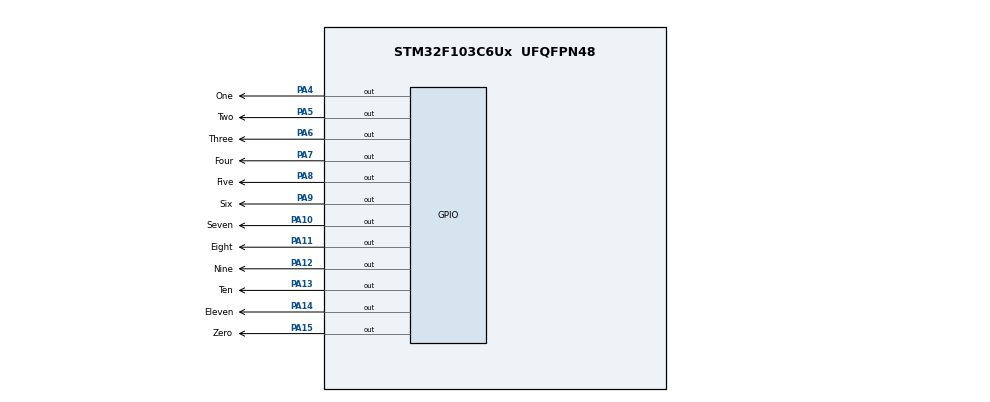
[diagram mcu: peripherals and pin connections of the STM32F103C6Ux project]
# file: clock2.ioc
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Mcu.Family=STM32F1
Mcu.Name=STM32F103C6Ux
Mcu.Package=UFQFPN48
NVIC.PriorityGroup=NVIC_PRIORITYGROUP_4
PA10.GPIO_Label=Seven
PA10.Signal=GPIO_Output
PA11.GPIO_Label=Eight
PA11.Signal=GPIO_Output
PA12.GPIO_Label=Nine
PA12.Signal=GPIO_Output
PA13.GPIO_Label=Ten
PA13.Signal=GPIO_Output
PA14.GPIO_Label=Eleven
PA14.Signal=GPIO_Output
PA15.GPIO_Label=Zero
PA15.Signal=GPIO_Output
PA4.GPIO_Label=One
PA4.Signal=GPIO_Output
PA5.GPIO_Label=Two
PA5.Signal=GPIO_Output
PA6.GPIO_Label=Three
PA6.Signal=GPIO_Output
PA7.GPIO_Label=Four
PA7.Signal=GPIO_Output
PA8.GPIO_Label=Five
PA8.Signal=GPIO_Output
PA9.GPIO_Label=Six
PA9.Signal=GPIO_Output
ProjectManager.HeapSize=0x200
ProjectManager.StackSize=0x400
ProjectManager.TargetToolchain=STM32CubeIDE
RCC.APB1Freq_Value=8000000
RCC.APB2Freq_Value=8000000
VP_SYS_VS_ND.Mode=No_Debug
board=custom

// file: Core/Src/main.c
/* USER CODE BEGIN Header */
/**
  ******************************************************************************
  * @file           : main.c
  * @brief          : Main program body
  ******************************************************************************
  * @attention
  *
  * <h2><center>&copy; Copyright (c) 2025 STMicroelectronics.
  * All rights reserved.</center></h2>
  *
  * This software component is licensed by ST under BSD 3-Clause license,
  * the "License"; You may not use this file except in compliance with the
  * License. You may obtain a copy of the License at:
  *                        opensource.org/licenses/BSD-3-Clause
  *
  ******************************************************************************
  */
/* USER CODE END Header */
#include "main.h"

void SystemClock_Config(void);
static void MX_GPIO_Init(void);

void setNumberOnClock(int num) {
	switch (num) {
		  case 0: HAL_GPIO_WritePin(Zero_GPIO_Port, Zero_Pin, SET); break;
		  case 1: HAL_GPIO_WritePin(One_GPIO_Port, One_Pin, SET); break;
		  case 2: HAL_GPIO_WritePin(Two_GPIO_Port, Two_Pin, SET); break;
		  case 3: HAL_GPIO_WritePin(Three_GPIO_Port, Three_Pin, SET); break;
		  case 4: HAL_GPIO_WritePin(Four_GPIO_Port, Four_Pin, SET); break;
		  case 5: HAL_GPIO_WritePin(Five_GPIO_Port, Five_Pin, SET); break;
		  case 6: HAL_GPIO_WritePin(Six_GPIO_Port, Six_Pin, SET); break;
		  case 7: HAL_GPIO_WritePin(Seven_GPIO_Port, Seven_Pin, SET); break;
		  case 8: HAL_GPIO_WritePin(Eight_GPIO_Port, Eight_Pin, SET); break;
		  case 9: HAL_GPIO_WritePin(Nine_GPIO_Port, Nine_Pin, SET); break;
		  case 10: HAL_GPIO_WritePin(Ten_GPIO_Port, Ten_Pin, SET); break;
		  case 11: HAL_GPIO_WritePin(Eleven_GPIO_Port, Eleven_Pin, SET); break;
		  default: break;
	}
}
void clearNumberOnClock(int num){
	switch (num) {
		  case 0: HAL_GPIO_WritePin(Zero_GPIO_Port, Zero_Pin, RESET); break;
		  case 1: HAL_GPIO_WritePin(One_GPIO_Port, One_Pin, RESET); break;
		  case 2: HAL_GPIO_WritePin(Two_GPIO_Port, Two_Pin, RESET); break;
		  case 3: HAL_GPIO_WritePin(Three_GPIO_Port, Three_Pin, RESET); break;
		  case 4: HAL_GPIO_WritePin(Four_GPIO_Port, Four_Pin, RESET); break;
		  case 5: HAL_GPIO_WritePin(Five_GPIO_Port, Five_Pin, RESET); break;
		  case 6: HAL_GPIO_WritePin(Six_GPIO_Port, Six_Pin, RESET); break;
		  case 7: HAL_GPIO_WritePin(Seven_GPIO_Port, Seven_Pin, RESET); break;
		  case 8: HAL_GPIO_WritePin(Eight_GPIO_Port, Eight_Pin, RESET); break;
		  case 9: HAL_GPIO_WritePin(Nine_GPIO_Port, Nine_Pin, RESET); break;
		  case 10: HAL_GPIO_WritePin(Ten_GPIO_Port, Ten_Pin, RESET); break;
		  case 11: HAL_GPIO_WritePin(Eleven_GPIO_Port, Eleven_Pin, RESET); break;
		  default: break;
	}
}

int main(void)
{

  /* MCU Configuration--------------------------------------------------------*/

  /* Reset of all peripherals, Initializes the Flash interface and the Systick. */
  HAL_Init();

  /* Configure the system clock */
  SystemClock_Config();

  /* Initialize all configured peripherals */
  MX_GPIO_Init();

  /* Infinite loop */
  /* USER CODE BEGIN WHILE */

  int step = 0;

  while (1)
  {
	  setNumberOnClock(step);
	  HAL_Delay(1000);
	  clearNumberOnClock(step);
	  step++;
	  if (step >= 12) step = 0;

    /* USER CODE END WHILE */

  }
}

void SystemClock_Config(void)
{
  RCC_OscInitTypeDef RCC_OscInitStruct = {0};
  RCC_ClkInitTypeDef RCC_ClkInitStruct = {0};

  /** Initializes the RCC Oscillators according to the specified parameters
  * in the RCC_OscInitTypeDef structure.
  */
  RCC_OscInitStruct.OscillatorType = RCC_OSCILLATORTYPE_HSI;
  RCC_OscInitStruct.HSIState = RCC_HSI_ON;
  RCC_OscInitStruct.HSICalibrationValue = RCC_HSICALIBRATION_DEFAULT;
  RCC_OscInitStruct.PLL.PLLState = RCC_PLL_NONE;
  if (HAL_RCC_OscConfig(&RCC_OscInitStruct) != HAL_OK)
  {
    Error_Handler();
  }
  /** Initializes the CPU, AHB and APB buses clocks
  */
  RCC_ClkInitStruct.ClockType = RCC_CLOCKTYPE_HCLK|RCC_CLOCKTYPE_SYSCLK
                              |RCC_CLOCKTYPE_PCLK1|RCC_CLOCKTYPE_PCLK2;
  RCC_ClkInitStruct.SYSCLKSource = RCC_SYSCLKSOURCE_HSI;
  RCC_ClkInitStruct.AHBCLKDivider = RCC_SYSCLK_DIV1;
  RCC_ClkInitStruct.APB1CLKDivider = RCC_HCLK_DIV1;
  RCC_ClkInitStruct.APB2CLKDivider = RCC_HCLK_DIV1;

  if (HAL_RCC_ClockConfig(&RCC_ClkInitStruct, FLASH_LATENCY_0) != HAL_OK)
  {
    Error_Handler();
  }
}

static void MX_GPIO_Init(void)
{
  GPIO_InitTypeDef GPIO_InitStruct = {0};

  /* GPIO Ports Clock Enable */
  __HAL_RCC_GPIOA_CLK_ENABLE();

  /*Configure GPIO pin Output Level */
  HAL_GPIO_WritePin(GPIOA, One_Pin|Two_Pin|Three_Pin|Four_Pin
                          |Five_Pin|Six_Pin|Seven_Pin|Eight_Pin
                          |Nine_Pin|Ten_Pin|Eleven_Pin|Zero_Pin, GPIO_PIN_RESET);

  /*Configure GPIO pins : One_Pin Two_Pin Three_Pin Four_Pin
                           Five_Pin Six_Pin Seven_Pin Eight_Pin
                           Nine_Pin Ten_Pin Eleven_Pin Zero_Pin */
  GPIO_InitStruct.Pin = One_Pin|Two_Pin|Three_Pin|Four_Pin
                          |Five_Pin|Six_Pin|Seven_Pin|Eight_Pin
                          |Nine_Pin|Ten_Pin|Eleven_Pin|Zero_Pin;
  GPIO_InitStruct.Mode = GPIO_MODE_OUTPUT_PP;
  GPIO_InitStruct.Pull = GPIO_NOPULL;
  GPIO_InitStruct.Speed = GPIO_SPEED_FREQ_LOW;
  HAL_GPIO_Init(GPIOA, &GPIO_InitStruct);

}

void Error_Handler(void)
{
  __disable_irq();
  while (1)
  {
  }
}

/************************ (C) COPYRIGHT STMicroelectronics *****END OF FILE****/
